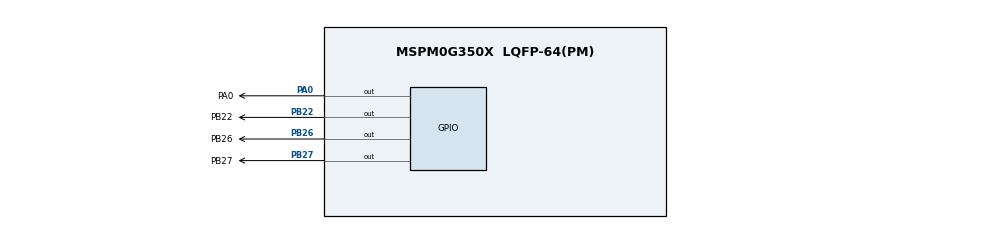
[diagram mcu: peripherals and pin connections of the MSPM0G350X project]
/**
 * @cliArgs --device "MSPM0G350X" --part "Default" --package "LQFP-64(PM)" --product "mspm0_sdk@2.01.00.03"
 * @versions {"tool":"1.21.0+3721"}
 */

/**
 * Import the modules used in this configuration.
 */
const GPIO    = scripting.addModule("/ti/driverlib/GPIO", {}, false);
const GPIO1   = GPIO.addInstance();
const GPIO2   = GPIO.addInstance();
const GPIO3   = GPIO.addInstance();
const GPIO4   = GPIO.addInstance();
const SYSCTL  = scripting.addModule("/ti/driverlib/SYSCTL");
const SYSTICK = scripting.addModule("/ti/driverlib/SYSTICK");

/**
 * Write custom configuration values to the imported modules.
 */
GPIO1.port                               = "PORTA";
GPIO1.$name                              = "LED1";
GPIO1.associatedPins[0].internalResistor = "PULL_DOWN";
GPIO1.associatedPins[0].assignedPin      = "0";
GPIO1.associatedPins[0].$name            = "PA0";
GPIO1.associatedPins[0].pin.$assign      = "PA0";

const Board = scripting.addModule("/ti/driverlib/Board", {}, false);

GPIO2.$name                         = "LED3";
GPIO2.port                          = "PORTB";
GPIO2.associatedPins[0].assignedPin = "26";
GPIO2.associatedPins[0].$name       = "PB26";
GPIO2.associatedPins[0].pin.$assign = "PB26";

GPIO3.$name                         = "LED2";
GPIO3.port                          = "PORTB";
GPIO3.associatedPins[0].$name       = "PB22";
GPIO3.associatedPins[0].assignedPin = "22";
GPIO3.associatedPins[0].pin.$assign = "PB22";

GPIO4.$name                         = "LED4";
GPIO4.port                          = "PORTB";
GPIO4.associatedPins[0].$name       = "PB27";
GPIO4.associatedPins[0].assignedPin = "27";
GPIO4.associatedPins[0].pin.$assign = "PB27";

SYSCTL.forceDefaultClkConfig = true;

SYSTICK.periodEnable      = true;
SYSTICK.interruptEnable   = true;
SYSTICK.systickEnable     = true;
SYSTICK.period            = 32000;
SYSTICK.interruptPriority = "0";

/**
 * Pinmux solution for unlocked pins/peripherals. This ensures that minor changes to the automatic solver in a future
 * version of the tool will not impact the pinmux you originally saw.  These lines can be completely deleted in order to
 * re-solve from scratch.
 */
Board.peripheral.$suggestSolution          = "DEBUGSS";
Board.peripheral.swclkPin.$suggestSolution = "PA20";
Board.peripheral.swdioPin.$suggestSolution = "PA19";
SYSCTL.peripheral.$suggestSolution         = "SYSCTL";
